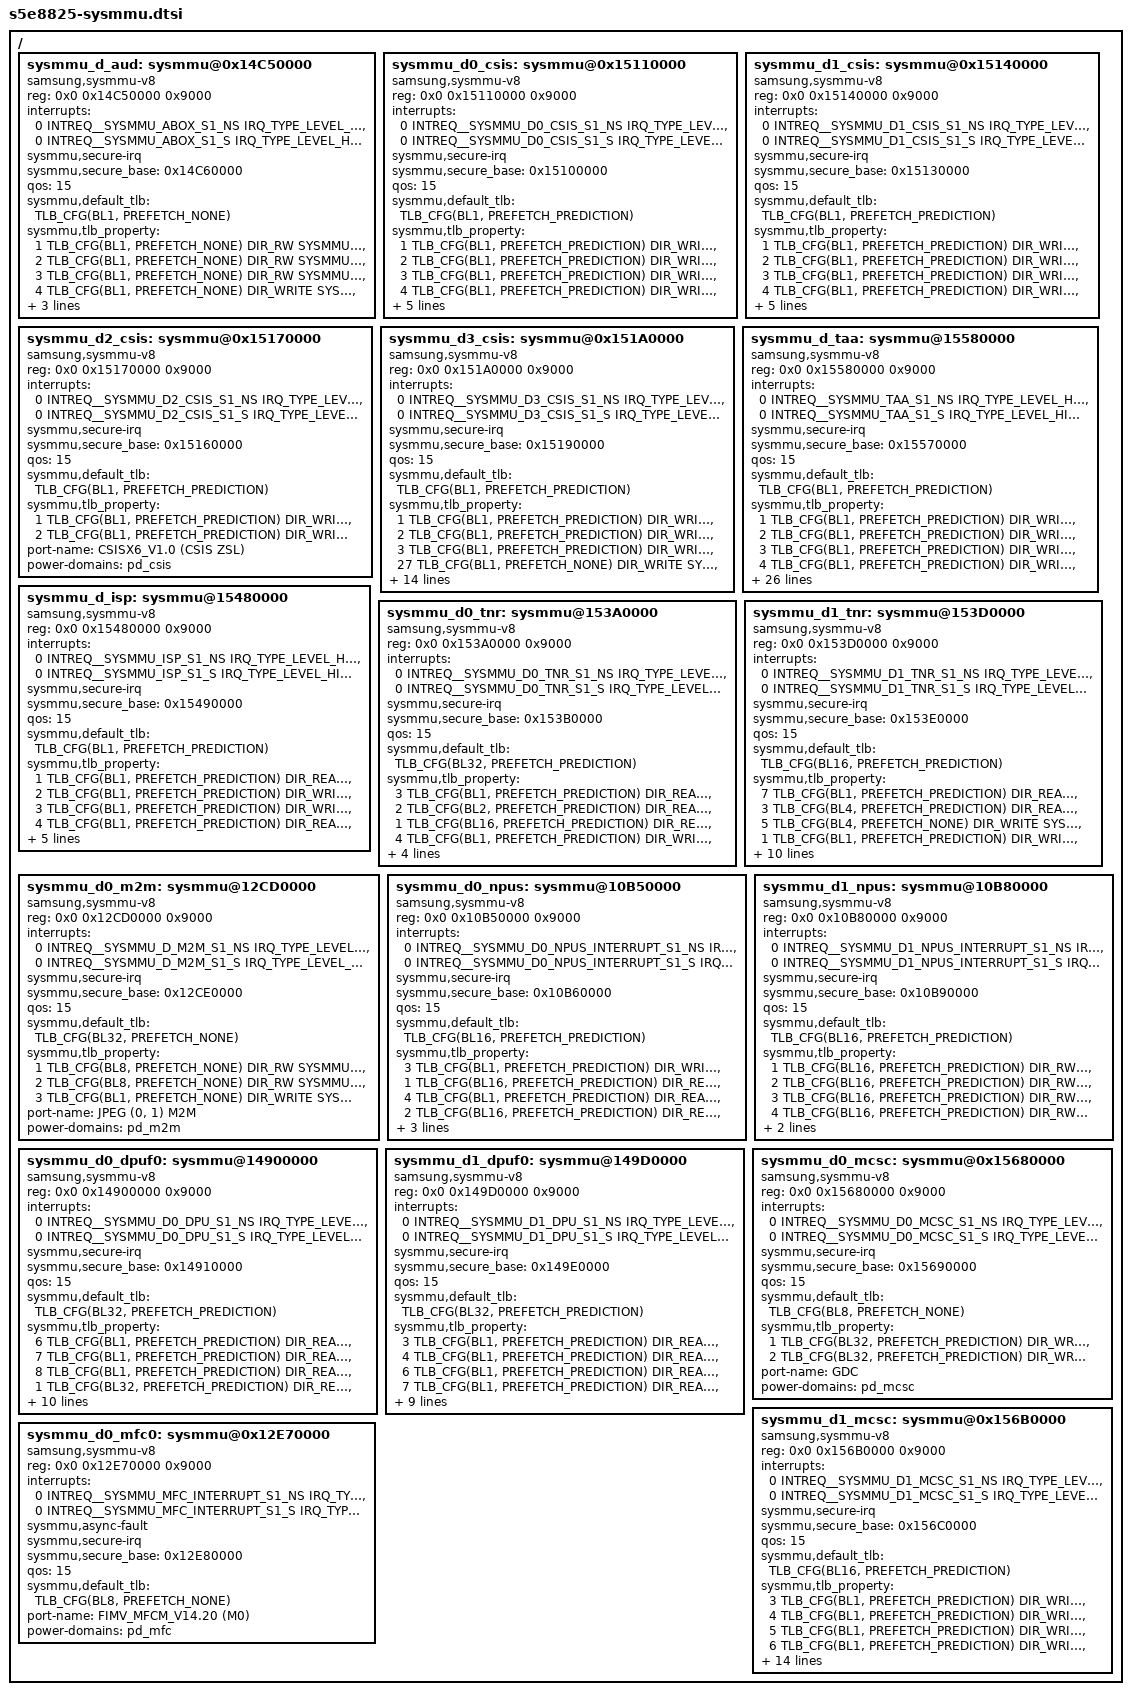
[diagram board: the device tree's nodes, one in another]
/*
 * SAMSUNG S5E8825 SoC device tree source
 *
 * Copyright (c) 2021 Samsung Electronics Co., Ltd.
 *      http://www.samsung.com
 *
 * SAMSUNG s5e8825 SoC device nodes are listed in this file.
 * EXYNOS1000 based board files can include this file and provide
 * values for board specfic bindings.
 *
 * This program is free software; you can redistribute it and/or modify
 * it under the terms of the GNU General Public License version 2 as
 * published by the Free Software Foundation.
 */

#include <dt-bindings/interrupt-controller/arm-gic.h>
#include <dt-bindings/soc/samsung,sysmmu-v8.h>

/ {
	sysmmu_d_aud: sysmmu@0x14C50000 {
		compatible = "samsung,sysmmu-v8";
		reg = <0x0 0x14C50000 0x9000>;
		interrupts = <0 INTREQ__SYSMMU_ABOX_S1_NS IRQ_TYPE_LEVEL_HIGH>,
				<0 INTREQ__SYSMMU_ABOX_S1_S IRQ_TYPE_LEVEL_HIGH>;
		sysmmu,secure-irq;
		sysmmu,secure_base = <0x14C60000>;
		qos = <15>;
		sysmmu,default_tlb = <TLB_CFG(BL1, PREFETCH_NONE)>;
		sysmmu,tlb_property =
			<1 TLB_CFG(BL1, PREFETCH_NONE) DIR_RW SYSMMU_ID_MASK(0x1, 0xF)>,
			<2 TLB_CFG(BL1, PREFETCH_NONE) DIR_RW SYSMMU_ID_MASK(0x3, 0xF)>,
			<3 TLB_CFG(BL1, PREFETCH_NONE) DIR_RW SYSMMU_ID_MASK(0x4, 0xF)>,
			<4 TLB_CFG(BL1, PREFETCH_NONE) DIR_WRITE SYSMMU_ID_MASK(0x6, 0xF)>,
			<5 TLB_CFG(BL1, PREFETCH_NONE) DIR_WRITE SYSMMU_ID_MASK(0x7, 0xF)>;
		port-name = "ABOX (CA32_0), ABOX (UDMA), ...";
		#iommu-cells = <0>;
		power-domains = <&pd_aud>;
	};

	sysmmu_d0_csis: sysmmu@0x15110000 {
		compatible = "samsung,sysmmu-v8";
		reg = <0x0 0x15110000 0x9000>;
		interrupts = <0 INTREQ__SYSMMU_D0_CSIS_S1_NS IRQ_TYPE_LEVEL_HIGH>,
				<0 INTREQ__SYSMMU_D0_CSIS_S1_S IRQ_TYPE_LEVEL_HIGH>;
		sysmmu,secure-irq;
		sysmmu,secure_base = <0x15100000>;
		qos = <15>;
		sysmmu,default_tlb = <TLB_CFG(BL1, PREFETCH_PREDICTION)>;
		sysmmu,tlb_property =
			<1 TLB_CFG(BL1, PREFETCH_PREDICTION) DIR_WRITE SYSMMU_ID_MASK(0x4, 0xF)>,
			<2 TLB_CFG(BL1, PREFETCH_PREDICTION) DIR_WRITE SYSMMU_ID_MASK(0x8, 0xF)>,
			<3 TLB_CFG(BL1, PREFETCH_PREDICTION) DIR_WRITE SYSMMU_ID_MASK(0xC, 0xF)>,
			<4 TLB_CFG(BL1, PREFETCH_PREDICTION) DIR_WRITE SYSMMU_ID_MASK(0x1, 0xF)>,
			<5 TLB_CFG(BL1, PREFETCH_PREDICTION) DIR_WRITE SYSMMU_ID_MASK(0x5, 0xF)>,
			<6 TLB_CFG(BL1, PREFETCH_PREDICTION) DIR_WRITE SYSMMU_ID_MASK(0x9, 0xF)>,
			<7 TLB_CFG(BL1, PREFETCH_PREDICTION) DIR_WRITE SYSMMU_ID_MASK(0xD, 0xF)>;
		port-name = "CSISX6_V1.0 (CSIS DMA0) (CSIS DMA1)";
		#iommu-cells = <0>;
		power-domains = <&pd_csis>;
	};

	sysmmu_d1_csis: sysmmu@0x15140000 {
		compatible = "samsung,sysmmu-v8";
		reg = <0x0 0x15140000 0x9000>;
		interrupts = <0 INTREQ__SYSMMU_D1_CSIS_S1_NS IRQ_TYPE_LEVEL_HIGH>,
				<0 INTREQ__SYSMMU_D1_CSIS_S1_S IRQ_TYPE_LEVEL_HIGH>;
		sysmmu,secure-irq;
		sysmmu,secure_base = <0x15130000>;
		qos = <15>;
		sysmmu,default_tlb = <TLB_CFG(BL1, PREFETCH_PREDICTION)>;
		sysmmu,tlb_property =
			<1 TLB_CFG(BL1, PREFETCH_PREDICTION) DIR_WRITE SYSMMU_ID_MASK(0x4, 0xF)>,
			<2 TLB_CFG(BL1, PREFETCH_PREDICTION) DIR_WRITE SYSMMU_ID_MASK(0x8, 0xF)>,
			<3 TLB_CFG(BL1, PREFETCH_PREDICTION) DIR_WRITE SYSMMU_ID_MASK(0xC, 0xF)>,
			<4 TLB_CFG(BL1, PREFETCH_PREDICTION) DIR_WRITE SYSMMU_ID_MASK(0x1, 0xF)>,
			<5 TLB_CFG(BL1, PREFETCH_PREDICTION) DIR_WRITE SYSMMU_ID_MASK(0x5, 0xF)>,
			<6 TLB_CFG(BL1, PREFETCH_PREDICTION) DIR_WRITE SYSMMU_ID_MASK(0x9, 0xF)>,
			<7 TLB_CFG(BL1, PREFETCH_PREDICTION) DIR_WRITE SYSMMU_ID_MASK(0xD, 0xF)>;
		port-name = "CSISX6_V1.0 (CSIS DMA2) (CSIS DMA3)";
		#iommu-cells = <0>;
                power-domains = <&pd_csis>;
	};

	sysmmu_d2_csis: sysmmu@0x15170000 {
		compatible = "samsung,sysmmu-v8";
		reg = <0x0 0x15170000 0x9000>;
		interrupts = <0 INTREQ__SYSMMU_D2_CSIS_S1_NS IRQ_TYPE_LEVEL_HIGH>,
				<0 INTREQ__SYSMMU_D2_CSIS_S1_S IRQ_TYPE_LEVEL_HIGH>;
		sysmmu,secure-irq;
		sysmmu,secure_base = <0x15160000>;
		qos = <15>;
		sysmmu,default_tlb = <TLB_CFG(BL1, PREFETCH_PREDICTION)>;
		sysmmu,tlb_property =
			<1 TLB_CFG(BL1, PREFETCH_PREDICTION) DIR_WRITE SYSMMU_ID_MASK(0x1, 0x7)>,
			<2 TLB_CFG(BL1, PREFETCH_PREDICTION) DIR_WRITE SYSMMU_ID_MASK(0x2, 0x7)>;
		port-name = "CSISX6_V1.0 (CSIS ZSL)";
		#iommu-cells = <0>;
                power-domains = <&pd_csis>;
	};

	sysmmu_d3_csis: sysmmu@0x151A0000 {
		compatible = "samsung,sysmmu-v8";
		reg = <0x0 0x151A0000 0x9000>;
		interrupts = <0 INTREQ__SYSMMU_D3_CSIS_S1_NS IRQ_TYPE_LEVEL_HIGH>,
				<0 INTREQ__SYSMMU_D3_CSIS_S1_S IRQ_TYPE_LEVEL_HIGH>;
		sysmmu,secure-irq;
		sysmmu,secure_base = <0x15190000>;
		qos = <15>;
		sysmmu,default_tlb = <TLB_CFG(BL1, PREFETCH_PREDICTION)>;
		sysmmu,tlb_property =
			<1  TLB_CFG(BL1, PREFETCH_PREDICTION) DIR_WRITE SYSMMU_ID_MASK(0x40, 0x7F)>,
			<2  TLB_CFG(BL1, PREFETCH_PREDICTION) DIR_WRITE SYSMMU_ID_MASK(0x8, 0x7F)>,
			<3  TLB_CFG(BL1, PREFETCH_PREDICTION) DIR_WRITE SYSMMU_ID_MASK(0x10, 0x7F)>,
			<27 TLB_CFG(BL1, PREFETCH_NONE) DIR_WRITE SYSMMU_ID_MASK(0x18, 0x7F)>,
			<28 TLB_CFG(BL1, PREFETCH_NONE) DIR_READ  SYSMMU_ID_MASK(0x20, 0x7F)>,
			<4  TLB_CFG(BL1, PREFETCH_PREDICTION) DIR_WRITE SYSMMU_ID_MASK(0x1, 0xF)>,
			<5  TLB_CFG(BL1, PREFETCH_PREDICTION) DIR_READ SYSMMU_ID_MASK(0x1, 0xF)>,
			<6  TLB_CFG(BL1, PREFETCH_PREDICTION) DIR_WRITE SYSMMU_ID_MASK(0x2, 0xF)>,
			<7  TLB_CFG(BL1, PREFETCH_PREDICTION) DIR_READ SYSMMU_ID_MASK(0x2, 0xF)>,
			<8  TLB_CFG(BL1, PREFETCH_PREDICTION) DIR_READ SYSMMU_ID_MASK(0x3, 0xF)>,
			<9  TLB_CFG(BL1, PREFETCH_PREDICTION) DIR_READ SYSMMU_ID_MASK(0x3, 0xF)>,
			<10 TLB_CFG(BL1, PREFETCH_PREDICTION) DIR_READ SYSMMU_ID_MASK(0x4, 0xF)>,
			<11 TLB_CFG(BL1, PREFETCH_PREDICTION) DIR_WRITE SYSMMU_ID_MASK(0x5, 0xF)>,
			<12 TLB_CFG(BL1, PREFETCH_PREDICTION) DIR_WRITE SYSMMU_ID_MASK(0x6, 0xF)>,
			<29 TLB_CFG(BL1, PREFETCH_NONE) DIR_WRITE SYSMMU_ID_MASK(0x7, 0xF)>;
		port-name = "CSISX6_STRP (0, 1, 2) CSISX6_VOTF (0, 1) PDP (IMG0, IMG1, IMG2)";
		#iommu-cells = <0>;
                power-domains = <&pd_csis>;
	};

	sysmmu_d_taa: sysmmu@15580000 {
		compatible = "samsung,sysmmu-v8";
		reg = <0x0 0x15580000 0x9000>;
		interrupts = <0 INTREQ__SYSMMU_TAA_S1_NS IRQ_TYPE_LEVEL_HIGH>,
			     <0 INTREQ__SYSMMU_TAA_S1_S  IRQ_TYPE_LEVEL_HIGH>;
		sysmmu,secure-irq;
		sysmmu,secure_base = <0x15570000>;
		qos = <15>;
		sysmmu,default_tlb = <TLB_CFG(BL1, PREFETCH_PREDICTION)>;
		sysmmu,tlb_property =
			<1  TLB_CFG(BL1, PREFETCH_PREDICTION) DIR_WRITE SYSMMU_ID_MASK(0x80, 0x1FF)>,
			<2  TLB_CFG(BL1, PREFETCH_PREDICTION) DIR_WRITE SYSMMU_ID_MASK(0x100, 0x1FF)>,
			<3  TLB_CFG(BL1, PREFETCH_PREDICTION) DIR_WRITE SYSMMU_ID_MASK(0x1, 0x1FF)>,
			<4  TLB_CFG(BL1, PREFETCH_PREDICTION) DIR_WRITE SYSMMU_ID_MASK(0x81, 0x1FF)>,
			<5  TLB_CFG(BL1, PREFETCH_PREDICTION) DIR_WRITE SYSMMU_ID_MASK(0x101, 0x1FF)>,
			<6  TLB_CFG(BL1, PREFETCH_PREDICTION) DIR_WRITE SYSMMU_ID_MASK(0x3, 0x1FF)>,
			<7  TLB_CFG(BL1, PREFETCH_PREDICTION) DIR_WRITE SYSMMU_ID_MASK(0x23, 0x1FF)>,
			<8  TLB_CFG(BL1, PREFETCH_PREDICTION) DIR_WRITE SYSMMU_ID_MASK(0x43, 0x1FF)>,
			<9  TLB_CFG(BL1, PREFETCH_PREDICTION) DIR_WRITE SYSMMU_ID_MASK(0x83, 0x1FF)>,
			<10 TLB_CFG(BL1, PREFETCH_PREDICTION) DIR_WRITE SYSMMU_ID_MASK(0xA3, 0x1FF)>,
			<11 TLB_CFG(BL1, PREFETCH_PREDICTION) DIR_WRITE SYSMMU_ID_MASK(0xC3, 0x1FF)>,
			<12 TLB_CFG(BL1, PREFETCH_PREDICTION) DIR_WRITE SYSMMU_ID_MASK(0x103, 0x1FF)>,
			<13 TLB_CFG(BL1, PREFETCH_PREDICTION) DIR_WRITE SYSMMU_ID_MASK(0x123, 0x1FF)>,
			<14 TLB_CFG(BL1, PREFETCH_PREDICTION) DIR_WRITE SYSMMU_ID_MASK(0x143, 0x1FF)>,
			<15 TLB_CFG(BL1, PREFETCH_PREDICTION) DIR_WRITE SYSMMU_ID_MASK(0x3, 0x1FF)>,
			<16 TLB_CFG(BL1, PREFETCH_PREDICTION) DIR_WRITE SYSMMU_ID_MASK(0x84, 0x1FF)>,
			<17 TLB_CFG(BL1, PREFETCH_PREDICTION) DIR_WRITE SYSMMU_ID_MASK(0x105, 0x1FF)>,
			<18 TLB_CFG(BL1, PREFETCH_PREDICTION) DIR_WRITE SYSMMU_ID_MASK(0x6, 0x1FF)>,
			<19 TLB_CFG(BL1, PREFETCH_PREDICTION) DIR_WRITE SYSMMU_ID_MASK(0x86, 0x1FF)>,
			<20 TLB_CFG(BL1, PREFETCH_PREDICTION) DIR_WRITE SYSMMU_ID_MASK(0x106, 0x1FF)>,
			<21 TLB_CFG(BL1, PREFETCH_PREDICTION) DIR_WRITE SYSMMU_ID_MASK(0x7, 0x1FF)>,
			<22 TLB_CFG(BL1, PREFETCH_PREDICTION) DIR_WRITE SYSMMU_ID_MASK(0x87, 0x1FF)>,
			<23 TLB_CFG(BL1, PREFETCH_PREDICTION) DIR_WRITE SYSMMU_ID_MASK(0x107, 0x1FF)>,
			<24 TLB_CFG(BL1, PREFETCH_PREDICTION) DIR_WRITE SYSMMU_ID_MASK(0x8, 0x1FF)>,
			<25 TLB_CFG(BL1, PREFETCH_PREDICTION) DIR_WRITE SYSMMU_ID_MASK(0x88, 0x1FF)>,
			<26 TLB_CFG(BL1, PREFETCH_PREDICTION) DIR_WRITE SYSMMU_ID_MASK(0x108, 0x1FF)>,
			<27 TLB_CFG(BL1, PREFETCH_PREDICTION) DIR_WRITE SYSMMU_ID_MASK(0x9, 0x1FF)>,
			<28 TLB_CFG(BL1, PREFETCH_PREDICTION) DIR_WRITE SYSMMU_ID_MASK(0xA, 0x1FF)>;
		port-name = "SIPU TAA";
		#iommu-cells = <0>;
                power-domains = <&pd_taa>;
	};

	sysmmu_d_isp: sysmmu@15480000 {
		compatible = "samsung,sysmmu-v8";
		reg = <0x0 0x15480000 0x9000>;
		interrupts = <0 INTREQ__SYSMMU_ISP_S1_NS IRQ_TYPE_LEVEL_HIGH>,
			     <0 INTREQ__SYSMMU_ISP_S1_S  IRQ_TYPE_LEVEL_HIGH>;

		sysmmu,secure-irq;
		sysmmu,secure_base = <0x15490000>;
		qos = <15>;
		sysmmu,default_tlb = <TLB_CFG(BL1, PREFETCH_PREDICTION)>;
		sysmmu,tlb_property =
			<1 TLB_CFG(BL1, PREFETCH_PREDICTION) DIR_READ SYSMMU_ID_MASK(0x4, 0xF)>,
			<2 TLB_CFG(BL1, PREFETCH_PREDICTION) DIR_WRITE SYSMMU_ID_MASK(0x0, 0xF)>,
			<3 TLB_CFG(BL1, PREFETCH_PREDICTION) DIR_WRITE SYSMMU_ID_MASK(0x8, 0xF)>,
			<4 TLB_CFG(BL1, PREFETCH_PREDICTION) DIR_READ SYSMMU_ID_MASK(0x1, 0xF)>,
			<5 TLB_CFG(BL1, PREFETCH_PREDICTION) DIR_READ SYSMMU_ID_MASK(0x2, 0xF)>,
			<6 TLB_CFG(BL1, PREFETCH_PREDICTION) DIR_WRITE SYSMMU_ID_MASK(0x2, 0xF)>,
			<7 TLB_CFG(BL1, PREFETCH_PREDICTION) DIR_READ SYSMMU_ID_MASK(0x3, 0xF)>;
		port-name = "ISP DNS (IMG, S0, S1, S2)";
		#iommu-cells = <0>;
                power-domains = <&pd_isp>;
	};

	sysmmu_d0_tnr: sysmmu@153A0000 {
		compatible = "samsung,sysmmu-v8";
		reg = <0x0 0x153A0000 0x9000>;
		interrupts = <0 INTREQ__SYSMMU_D0_TNR_S1_NS IRQ_TYPE_LEVEL_HIGH>,
			     <0 INTREQ__SYSMMU_D0_TNR_S1_S  IRQ_TYPE_LEVEL_HIGH>;

		sysmmu,secure-irq;
		sysmmu,secure_base = <0x153B0000>;
		qos = <15>;
		sysmmu,default_tlb = <TLB_CFG(BL32, PREFETCH_PREDICTION)>;
		sysmmu,tlb_property =
			<3 TLB_CFG(BL1, PREFETCH_PREDICTION) DIR_READ SYSMMU_ID_MASK(0x0, 0xF)>,
			<2 TLB_CFG(BL2, PREFETCH_PREDICTION) DIR_READ SYSMMU_ID_MASK(0x8, 0xF)>,
			<1 TLB_CFG(BL16, PREFETCH_PREDICTION) DIR_READ SYSMMU_ID_MASK(0x2, 0xF)>,
			<4 TLB_CFG(BL1, PREFETCH_PREDICTION) DIR_WRITE SYSMMU_ID_MASK(0x3, 0xF)>,
			<5 TLB_CFG(BL1, PREFETCH_PREDICTION) DIR_WRITE SYSMMU_ID_MASK(0xB, 0xF)>,
			<6 TLB_CFG(BL1, PREFETCH_PREDICTION) DIR_WRITE SYSMMU_ID_MASK(0x4, 0xF)>;
		port-name = "TNR D0 (M0, M3, M6)";
		#iommu-cells = <0>;
                power-domains = <&pd_tnr>;
	};

	sysmmu_d1_tnr: sysmmu@153D0000 {
		compatible = "samsung,sysmmu-v8";
		reg = <0x0 0x153D0000 0x9000>;
		interrupts = <0 INTREQ__SYSMMU_D1_TNR_S1_NS IRQ_TYPE_LEVEL_HIGH>,
			     <0 INTREQ__SYSMMU_D1_TNR_S1_S  IRQ_TYPE_LEVEL_HIGH>;

		sysmmu,secure-irq;
		sysmmu,secure_base = <0x153E0000>;
		qos = <15>;
		sysmmu,default_tlb = <TLB_CFG(BL16, PREFETCH_PREDICTION)>;
		sysmmu,tlb_property =
			<7 TLB_CFG(BL1, PREFETCH_PREDICTION) DIR_READ  SYSMMU_ID_MASK(0x0, 0x1F)>,
			<3 TLB_CFG(BL4, PREFETCH_PREDICTION) DIR_READ  SYSMMU_ID_MASK(0x1, 0x1F)>,
			<5 TLB_CFG(BL4, PREFETCH_NONE) DIR_WRITE SYSMMU_ID_MASK(0x1, 0x1F)>,
			<1 TLB_CFG(BL1, PREFETCH_PREDICTION) DIR_WRITE SYSMMU_ID_MASK(0x2, 0x1F)>,
			<8 TLB_CFG(BL1, PREFETCH_PREDICTION) DIR_READ  SYSMMU_ID_MASK(0x3, 0x1F)>,
			<10 TLB_CFG(BL1, PREFETCH_NONE) DIR_WRITE SYSMMU_ID_MASK(0x4, 0x1F)>,
			<4 TLB_CFG(BL4, PREFETCH_PREDICTION) DIR_READ  SYSMMU_ID_MASK(0x5, 0x1F)>,
			<6 TLB_CFG(BL4, PREFETCH_NONE) DIR_WRITE SYSMMU_ID_MASK(0x5, 0x1F)>,
			<1 TLB_CFG(BL16, PREFETCH_PREDICTION) DIR_READ  SYSMMU_ID_MASK(0x6, 0x1F)>,
			<9 TLB_CFG(BL1, PREFETCH_PREDICTION) DIR_WRITE SYSMMU_ID_MASK(0x6, 0x1F)>,
			<2 TLB_CFG(BL16, PREFETCH_PREDICTION) DIR_READ  SYSMMU_ID_MASK(0x7, 0x1F)>,
			<11 TLB_CFG(BL1, PREFETCH_NONE) DIR_WRITE SYSMMU_ID_MASK(0x8, 0x1F)>;
		port-name = "TNR (M1, M2, M4 M5)";
		#iommu-cells = <0>;
                power-domains = <&pd_tnr>;
	};

	sysmmu_d0_m2m: sysmmu@12CD0000 {
		compatible = "samsung,sysmmu-v8";
		reg = <0x0 0x12CD0000 0x9000>;
		interrupts = <0 INTREQ__SYSMMU_D_M2M_S1_NS IRQ_TYPE_LEVEL_HIGH>,
			     <0 INTREQ__SYSMMU_D_M2M_S1_S  IRQ_TYPE_LEVEL_HIGH>;

		sysmmu,secure-irq;
		sysmmu,secure_base = <0x12CE0000>;
		qos = <15>;
		sysmmu,default_tlb = <TLB_CFG(BL32, PREFETCH_NONE)>;
		sysmmu,tlb_property =
			<1 TLB_CFG(BL8, PREFETCH_NONE) DIR_RW SYSMMU_ID_MASK(0x0, 0x3)>,
			<2 TLB_CFG(BL8, PREFETCH_NONE) DIR_RW SYSMMU_ID_MASK(0x1, 0x3)>,
			<3 TLB_CFG(BL1, PREFETCH_NONE) DIR_WRITE SYSMMU_ID_MASK(0x6, 0x7)>;
		port-name = "JPEG (0, 1) M2M";
		#iommu-cells = <0>;
                power-domains = <&pd_m2m>;
	};

	sysmmu_d0_npus: sysmmu@10B50000 {
		compatible = "samsung,sysmmu-v8";
		reg = <0x0 0x10B50000 0x9000>;
		interrupts = <0 INTREQ__SYSMMU_D0_NPUS_INTERRUPT_S1_NS IRQ_TYPE_LEVEL_HIGH>,
			     <0 INTREQ__SYSMMU_D0_NPUS_INTERRUPT_S1_S  IRQ_TYPE_LEVEL_HIGH>;

		sysmmu,secure-irq;
		sysmmu,secure_base = <0x10B60000>;
		qos = <15>;
		sysmmu,default_tlb = <TLB_CFG(BL16, PREFETCH_PREDICTION)>;
		sysmmu,tlb_property =
			<3  TLB_CFG(BL1, PREFETCH_PREDICTION) DIR_WRITE SYSMMU_ID_MASK(0x10, 0x3)>,
			<1  TLB_CFG(BL16, PREFETCH_PREDICTION) DIR_READ SYSMMU_ID_MASK(0x0, 0x7)>,
			<4  TLB_CFG(BL1, PREFETCH_PREDICTION) DIR_READ SYSMMU_ID_MASK(0x10, 0x7)>,
			<2  TLB_CFG(BL16, PREFETCH_PREDICTION) DIR_READ SYSMMU_ID_MASK(0x100, 0x7)>,
			<5  TLB_CFG(BL1, PREFETCH_PREDICTION) DIR_READ SYSMMU_ID_MASK(0x110, 0x7)>;

		port-name = "IP NPUS FLC00";
		#iommu-cells = <0>;
                power-domains = <&pd_npus>;
	};

	sysmmu_d1_npus: sysmmu@10B80000 {
		compatible = "samsung,sysmmu-v8";
		reg = <0x0 0x10B80000 0x9000>;
		interrupts = <0 INTREQ__SYSMMU_D1_NPUS_INTERRUPT_S1_NS IRQ_TYPE_LEVEL_HIGH>,
			     <0 INTREQ__SYSMMU_D1_NPUS_INTERRUPT_S1_S  IRQ_TYPE_LEVEL_HIGH>;

		sysmmu,secure-irq;
		sysmmu,secure_base = <0x10B90000>;
		qos = <15>;
		sysmmu,default_tlb = <TLB_CFG(BL16, PREFETCH_PREDICTION)>;
		sysmmu,tlb_property =
			<1  TLB_CFG(BL16, PREFETCH_PREDICTION) DIR_RW SYSMMU_ID_MASK(0x110, 0x37)>,
			<2  TLB_CFG(BL16, PREFETCH_PREDICTION) DIR_RW SYSMMU_ID_MASK(0x10, 0x37)>,
			<3  TLB_CFG(BL16, PREFETCH_PREDICTION) DIR_RW SYSMMU_ID_MASK(0x10010, 0x37)>,
			<4  TLB_CFG(BL16, PREFETCH_PREDICTION) DIR_RW SYSMMU_ID_MASK(0x1010, 0x37)>;

		port-name = "IP NPUS SDMA";
		#iommu-cells = <0>;
                power-domains = <&pd_npus>;
	};

	sysmmu_d0_dpuf0: sysmmu@14900000 {
		compatible = "samsung,sysmmu-v8";
		reg = <0x0 0x14900000 0x9000>;
		interrupts = <0 INTREQ__SYSMMU_D0_DPU_S1_NS IRQ_TYPE_LEVEL_HIGH>,
				<0 INTREQ__SYSMMU_D0_DPU_S1_S IRQ_TYPE_LEVEL_HIGH>;
		sysmmu,secure-irq;
		sysmmu,secure_base = <0x14910000>;
		qos = <15>;
		sysmmu,default_tlb = <TLB_CFG(BL32, PREFETCH_PREDICTION)>;
		sysmmu,tlb_property =
			<6 TLB_CFG(BL1, PREFETCH_PREDICTION) DIR_READ SYSMMU_ID_MASK(0x1E, 0x1F)>,
			<7 TLB_CFG(BL1, PREFETCH_PREDICTION) DIR_READ SYSMMU_ID_MASK(0x1F, 0x1F)>,
			<8 TLB_CFG(BL1, PREFETCH_PREDICTION) DIR_READ SYSMMU_ID_MASK(0x0, 0xF)>,
			<1 TLB_CFG(BL32, PREFETCH_PREDICTION) DIR_READ SYSMMU_ID_MASK(0x5, 0xF)>,
			<3 TLB_CFG(BL1, PREFETCH_PREDICTION) DIR_READ SYSMMU_ID_MASK(0x6, 0xF)>,
			<9 TLB_CFG(BL1, PREFETCH_PREDICTION) DIR_READ SYSMMU_ID_MASK(0x7, 0xF)>,
			<2 TLB_CFG(BL16, PREFETCH_PREDICTION) DIR_READ SYSMMU_ID_MASK(0x8, 0xF)>,
			<4 TLB_CFG(BL1, PREFETCH_PREDICTION) DIR_READ SYSMMU_ID_MASK(0xA, 0xF)>,
			<5 TLB_CFG(BL1, PREFETCH_PREDICTION) DIR_READ SYSMMU_ID_MASK(0xC, 0xF)>,
			<10 TLB_CFG(BL1, PREFETCH_PREDICTION) DIR_READ SYSMMU_ID_MASK(0xD, 0xF)>,
			<11 TLB_CFG(BL1, PREFETCH_PREDICTION) DIR_READ SYSMMU_ID_MASK(0xE, 0x1F)>,
			<12 TLB_CFG(BL1, PREFETCH_PREDICTION) DIR_READ SYSMMU_ID_MASK(0xF, 0x1F)>;
		port-name = "DPUF0 D0";
		#iommu-cells = <0>;
                power-domains = <&pd_dpu>;
	};

	sysmmu_d1_dpuf0: sysmmu@149D0000 {
		compatible = "samsung,sysmmu-v8";
		reg = <0x0 0x149D0000 0x9000>;
		interrupts = <0 INTREQ__SYSMMU_D1_DPU_S1_NS IRQ_TYPE_LEVEL_HIGH>,
				<0 INTREQ__SYSMMU_D1_DPU_S1_S IRQ_TYPE_LEVEL_HIGH>;
		sysmmu,secure-irq;
		sysmmu,secure_base = <0x149E0000>;
		qos = <15>;
		sysmmu,default_tlb = <TLB_CFG(BL32, PREFETCH_PREDICTION)>;
		sysmmu,tlb_property =
			<3 TLB_CFG(BL1, PREFETCH_PREDICTION) DIR_READ SYSMMU_ID_MASK(0x2, 0xF)>,
			<4 TLB_CFG(BL1, PREFETCH_PREDICTION) DIR_READ SYSMMU_ID_MASK(0x4, 0xF)>,
			<6 TLB_CFG(BL1, PREFETCH_PREDICTION) DIR_READ SYSMMU_ID_MASK(0x5, 0xF)>,
			<7 TLB_CFG(BL1, PREFETCH_PREDICTION) DIR_READ SYSMMU_ID_MASK(0x8, 0xF)>,
			<1 TLB_CFG(BL32, PREFETCH_PREDICTION) DIR_READ SYSMMU_ID_MASK(0xC, 0xF)>,
			<2 TLB_CFG(BL16, PREFETCH_PREDICTION) DIR_READ SYSMMU_ID_MASK(0xD, 0xF)>,
			<5 TLB_CFG(BL1, PREFETCH_PREDICTION) DIR_READ SYSMMU_ID_MASK(0xE, 0x1F)>,
			<8 TLB_CFG(BL1, PREFETCH_PREDICTION) DIR_READ SYSMMU_ID_MASK(0xF, 0x1F)>,
			<9 TLB_CFG(BL1, PREFETCH_PREDICTION) DIR_WRITE  SYSMMU_ID_MASK(0x0, 0xF)>,
			<10 TLB_CFG(BL1, PREFETCH_PREDICTION) DIR_WRITE SYSMMU_ID_MASK(0x1, 0xF)>,
			<13 TLB_CFG(BL1, PREFETCH_PREDICTION) DIR_WRITE SYSMMU_ID_MASK(0x8, 0xF)>;
		port-name = "DPUF0 D1";
		#iommu-cells = <0>;
                power-domains = <&pd_dpu>;
	};

	sysmmu_d0_mcsc: sysmmu@0x15680000 {
		compatible = "samsung,sysmmu-v8";
		reg = <0x0 0x15680000 0x9000>;
		interrupts = <0 INTREQ__SYSMMU_D0_MCSC_S1_NS IRQ_TYPE_LEVEL_HIGH>,
				<0 INTREQ__SYSMMU_D0_MCSC_S1_S IRQ_TYPE_LEVEL_HIGH>;
		sysmmu,secure-irq;
		sysmmu,secure_base = <0x15690000>;
		qos = <15>;
		sysmmu,default_tlb = <TLB_CFG(BL8, PREFETCH_NONE)>;
		sysmmu,tlb_property =
			<1 TLB_CFG(BL32, PREFETCH_PREDICTION) DIR_WRITE SYSMMU_ID_MASK(0x0, 0x1)>,
			<2 TLB_CFG(BL32, PREFETCH_PREDICTION) DIR_WRITE SYSMMU_ID_MASK(0x1, 0x1)>;
		port-name = "GDC";
		#iommu-cells = <0>;
                power-domains = <&pd_mcsc>;
	};

	sysmmu_d1_mcsc: sysmmu@0x156B0000 {
		compatible = "samsung,sysmmu-v8";
		reg = <0x0 0x156B0000 0x9000>;
		interrupts = <0 INTREQ__SYSMMU_D1_MCSC_S1_NS IRQ_TYPE_LEVEL_HIGH>,
				<0 INTREQ__SYSMMU_D1_MCSC_S1_S IRQ_TYPE_LEVEL_HIGH>;
		sysmmu,secure-irq;
		sysmmu,secure_base = <0x156C0000>;
		qos = <15>;
		sysmmu,default_tlb = <TLB_CFG(BL16, PREFETCH_PREDICTION)>;
		sysmmu,tlb_property =
			<3 TLB_CFG(BL1, PREFETCH_PREDICTION) DIR_WRITE SYSMMU_ID_MASK(0x0, 0x7F)>,
			<4 TLB_CFG(BL1, PREFETCH_PREDICTION) DIR_WRITE SYSMMU_ID_MASK(0x8, 0x7F)>,
			<5 TLB_CFG(BL1, PREFETCH_PREDICTION) DIR_WRITE SYSMMU_ID_MASK(0x10, 0x7F)>,
			<6 TLB_CFG(BL1, PREFETCH_PREDICTION) DIR_WRITE SYSMMU_ID_MASK(0x18, 0x7F)>,
			<7 TLB_CFG(BL1, PREFETCH_PREDICTION) DIR_WRITE SYSMMU_ID_MASK(0x20, 0x7F)>,
			<8 TLB_CFG(BL1, PREFETCH_PREDICTION) DIR_WRITE SYSMMU_ID_MASK(0x28, 0x7F)>,
			<9 TLB_CFG(BL1, PREFETCH_PREDICTION) DIR_WRITE SYSMMU_ID_MASK(0x30, 0x7F)>,
			<10 TLB_CFG(BL1, PREFETCH_PREDICTION) DIR_WRITE SYSMMU_ID_MASK(0x38, 0x7F)>,
			<11 TLB_CFG(BL1, PREFETCH_PREDICTION) DIR_WRITE SYSMMU_ID_MASK(0x48, 0x7F)>,
			<12 TLB_CFG(BL1, PREFETCH_PREDICTION) DIR_READ SYSMMU_ID_MASK(0x0, 0x7F)>,
			<13 TLB_CFG(BL1, PREFETCH_PREDICTION) DIR_READ SYSMMU_ID_MASK(0x8, 0x7F)>,
			<14 TLB_CFG(BL1, PREFETCH_PREDICTION) DIR_READ SYSMMU_ID_MASK(0x10, 0x7F)>,
			<1 TLB_CFG(BL4, PREFETCH_PREDICTION) DIR_READ SYSMMU_ID_MASK(0x1, 0x1F)>,
			<2 TLB_CFG(BL4, PREFETCH_NONE) DIR_WRITE SYSMMU_ID_MASK(0x1, 0x1F)>,
			<15 TLB_CFG(BL1, PREFETCH_PREDICTION) DIR_WRITE SYSMMU_ID_MASK(0x2, 0x1F)>,
			<16 TLB_CFG(BL1, PREFETCH_NONE) DIR_WRITE SYSMMU_ID_MASK(0x4, 0x1F)>;
		port-name = "MCSC ORBMCH";
		#iommu-cells = <0>;
                power-domains = <&pd_mcsc>;
	};

	sysmmu_d0_mfc0: sysmmu@0x12E70000 {
		compatible = "samsung,sysmmu-v8";
		reg = <0x0 0x12E70000 0x9000>;
		interrupts = <0 INTREQ__SYSMMU_MFC_INTERRUPT_S1_NS IRQ_TYPE_LEVEL_HIGH>,
				<0 INTREQ__SYSMMU_MFC_INTERRUPT_S1_S IRQ_TYPE_LEVEL_HIGH>;
		sysmmu,async-fault;
		sysmmu,secure-irq;
		sysmmu,secure_base = <0x12E80000>;
		qos = <15>;
		sysmmu,default_tlb = <TLB_CFG(BL8, PREFETCH_NONE)>;
		port-name = "FIMV_MFCM_V14.20 (M0)";
		#iommu-cells = <0>;
                power-domains = <&pd_mfc>;
	};
};
